# ioam3358 register map
Registers are 32-bit, access not given, no defined reset value unless marked. A register's access mark holds for its fields unless they carry their own. Addresses are absolute; registers are grouped by the start of their names; [hi:lo] are bit positions; {n}, {i} and the like mark numbered series; 'fields as' and 'values as' point back to an identical list.

## CPSW
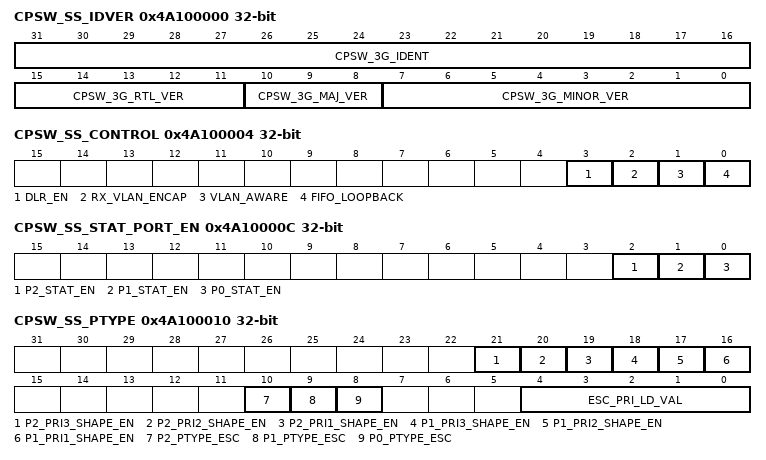
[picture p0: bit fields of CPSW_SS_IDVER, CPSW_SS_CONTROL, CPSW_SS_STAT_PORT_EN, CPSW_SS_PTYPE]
0x4A100000 CPSW_SS_IDVER
  [31:16] CPSW_3G_IDENT, [15:11] CPSW_3G_RTL_VER, [10:8] CPSW_3G_MAJ_VER, [7:0] CPSW_3G_MINOR_VER
0x4A100004 CPSW_SS_CONTROL
  [3] DLR_EN, [2] RX_VLAN_ENCAP, [1] VLAN_AWARE, [0] FIFO_LOOPBACK
0x4A100008 CPSW_SS_SOFT_RESET
  [0] SOFT_RESET
0x4A10000C CPSW_SS_STAT_PORT_EN
  [2] P2_STAT_EN, [1] P1_STAT_EN, [0] P0_STAT_EN
0x4A100010 CPSW_SS_PTYPE
  [21] P2_PRI3_SHAPE_EN, [20] P2_PRI2_SHAPE_EN, [19] P2_PRI1_SHAPE_EN, [18] P1_PRI3_SHAPE_EN, [17] P1_PRI2_SHAPE_EN, [16] P1_PRI1_SHAPE_EN, [10] P2_PTYPE_ESC, [9] P1_PTYPE_ESC, [8] P0_PTYPE_ESC, [4:0] ESC_PRI_LD_VAL
0x4A100014 CPSW_SS_SOFT_IDLE
  [0] SOFT_IDLE
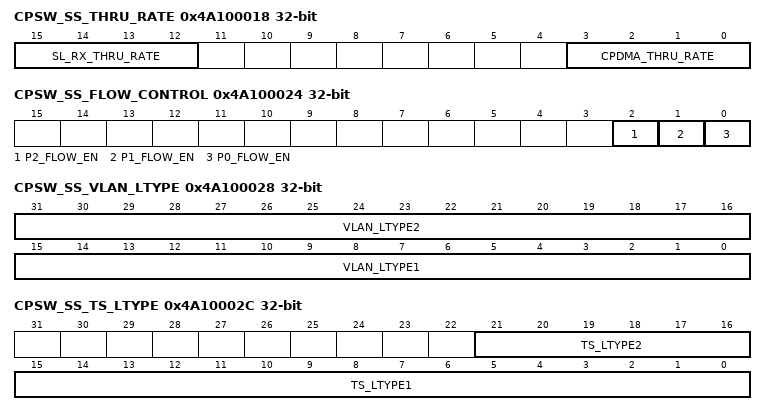
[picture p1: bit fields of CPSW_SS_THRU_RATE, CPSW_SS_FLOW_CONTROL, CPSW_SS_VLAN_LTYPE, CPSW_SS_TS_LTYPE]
0x4A100018 CPSW_SS_THRU_RATE
  [15:12] SL_RX_THRU_RATE, [3:0] CPDMA_THRU_RATE
0x4A10001C CPSW_SS_GAP_THRESH
  [4:0] GAP_THRESH
0x4A100020 CPSW_SS_TX_START_WDS
  [10:0] TX_START_WDS
0x4A100024 CPSW_SS_FLOW_CONTROL
  [2] P2_FLOW_EN, [1] P1_FLOW_EN, [0] P0_FLOW_EN
0x4A100028 CPSW_SS_VLAN_LTYPE
  [31:16] VLAN_LTYPE2, [15:0] VLAN_LTYPE1
0x4A10002C CPSW_SS_TS_LTYPE
  [21:16] TS_LTYPE2, [15:0] TS_LTYPE1
0x4A100030 CPSW_SS_DLR_LTYPE
  [15:0] DLR_LTYPE
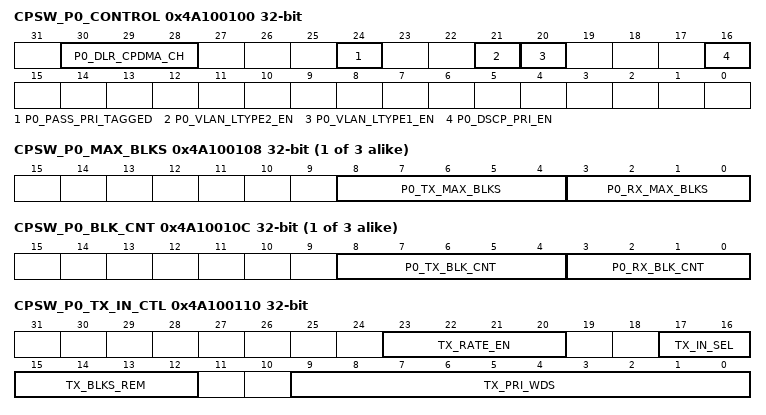
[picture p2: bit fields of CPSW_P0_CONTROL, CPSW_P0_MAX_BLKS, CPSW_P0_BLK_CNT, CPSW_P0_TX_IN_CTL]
0x4A100100 CPSW_P0_CONTROL
  [30:28] P0_DLR_CPDMA_CH, [24] P0_PASS_PRI_TAGGED, [21] P0_VLAN_LTYPE2_EN, [20] P0_VLAN_LTYPE1_EN, [16] P0_DSCP_PRI_EN
{0x4A100108+0x100*i} CPSW_P{i}_MAX_BLKS (i=0..2)
  [8:4] P{i}_TX_MAX_BLKS, [3:0] P{i}_RX_MAX_BLKS
{0x4A10010C+0x100*i} CPSW_P{i}_BLK_CNT (i=0..2)
  [8:4] P{i}_TX_BLK_CNT, [3:0] P{i}_RX_BLK_CNT
0x4A100110 CPSW_P0_TX_IN_CTL
  [23:20] TX_RATE_EN, [17:16] TX_IN_SEL, [15:12] TX_BLKS_REM, [9:0] TX_PRI_WDS
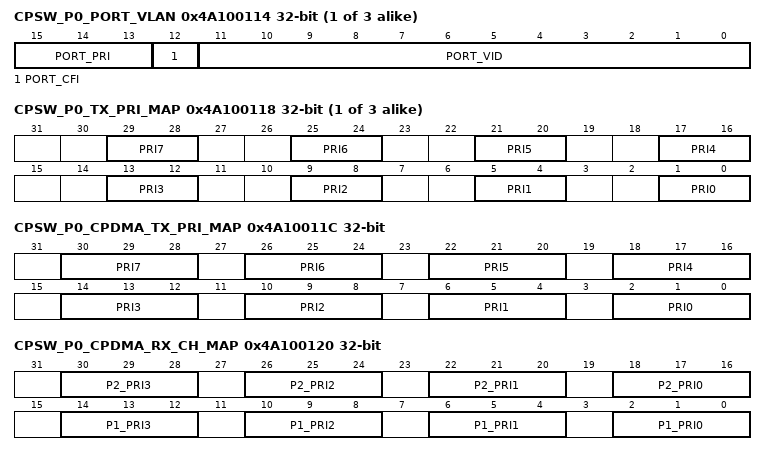
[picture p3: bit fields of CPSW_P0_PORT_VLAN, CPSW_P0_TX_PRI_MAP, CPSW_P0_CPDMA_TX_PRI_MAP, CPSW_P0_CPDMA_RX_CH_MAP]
{0x4A100114+0x100*i} CPSW_P{i}_PORT_VLAN (i=0..2)
  [15:13] PORT_PRI, [12] PORT_CFI, [11:0] PORT_VID
{0x4A100118+0x100*i} CPSW_P{i}_TX_PRI_MAP (i=0..2)
  [4n+1:4n] PRI{n} (n=0..7)
0x4A10011C CPSW_P0_CPDMA_TX_PRI_MAP
  [4n+2:4n] PRI{n} (n=0..7)
0x4A100120 CPSW_P0_CPDMA_RX_CH_MAP
  [4n+18:4n+16] P2_PRI{n} (n=0..3), [4n+2:4n] P1_PRI{n} (n=0..3)
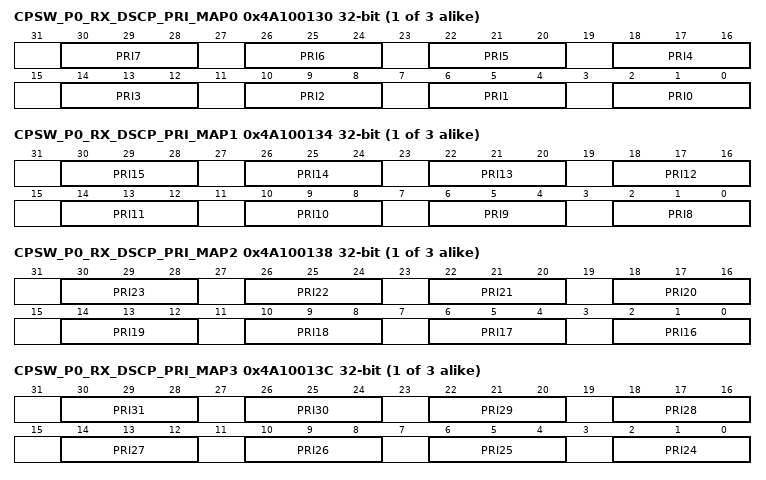
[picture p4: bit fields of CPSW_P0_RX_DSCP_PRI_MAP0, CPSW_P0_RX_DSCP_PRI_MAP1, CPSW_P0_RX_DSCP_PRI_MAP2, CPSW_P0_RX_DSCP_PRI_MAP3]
{0x4A100130+0x100*i} CPSW_P{i}_RX_DSCP_PRI_MAP0 (i=0..2)
  [4n+2:4n] PRI{n} (n=0..7)
{0x4A100134+0x100*i} CPSW_P{i}_RX_DSCP_PRI_MAP1 (i=0..2)
  [4n-30:4n-32] PRI{n} (n=8..15)
{0x4A100138+0x100*i} CPSW_P{i}_RX_DSCP_PRI_MAP2 (i=0..2)
  [4n-62:4n-64] PRI{n} (n=16..23)
{0x4A10013C+0x100*i} CPSW_P{i}_RX_DSCP_PRI_MAP3 (i=0..2)
  [4n-94:4n-96] PRI{n} (n=24..31)
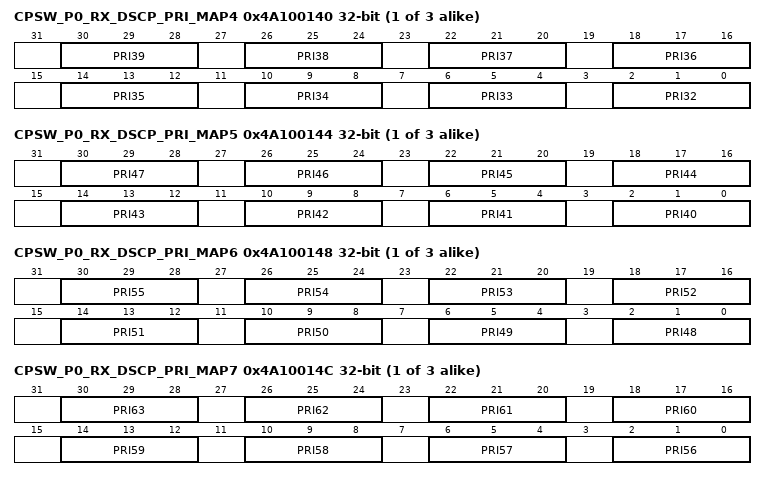
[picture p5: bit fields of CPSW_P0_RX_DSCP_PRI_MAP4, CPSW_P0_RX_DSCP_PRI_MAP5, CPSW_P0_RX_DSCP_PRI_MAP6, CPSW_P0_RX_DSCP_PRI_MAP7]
{0x4A100140+0x100*i} CPSW_P{i}_RX_DSCP_PRI_MAP4 (i=0..2)
  [4n-126:4n-128] PRI{n} (n=32..39)
{0x4A100144+0x100*i} CPSW_P{i}_RX_DSCP_PRI_MAP5 (i=0..2)
  [4n-158:4n-160] PRI{n} (n=40..47)
{0x4A100148+0x100*i} CPSW_P{i}_RX_DSCP_PRI_MAP6 (i=0..2)
  [4n-190:4n-192] PRI{n} (n=48..55)
{0x4A10014C+0x100*i} CPSW_P{i}_RX_DSCP_PRI_MAP7 (i=0..2)
  [4n-222:4n-224] PRI{n} (n=56..63)
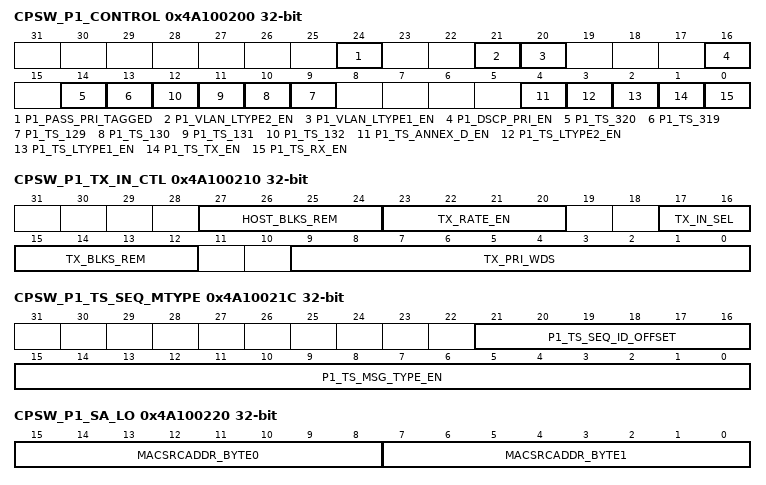
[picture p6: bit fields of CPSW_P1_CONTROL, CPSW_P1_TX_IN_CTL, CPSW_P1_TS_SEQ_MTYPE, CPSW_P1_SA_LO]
0x4A100200 CPSW_P1_CONTROL
  [24] P1_PASS_PRI_TAGGED, [21] P1_VLAN_LTYPE2_EN, [20] P1_VLAN_LTYPE1_EN, [16] P1_DSCP_PRI_EN, [14] P1_TS_320, [13] P1_TS_319, [n-120] P1_TS_{n} (n=129..132), [4] P1_TS_ANNEX_D_EN, [3] P1_TS_LTYPE2_EN, [2] P1_TS_LTYPE1_EN, [1] P1_TS_TX_EN, [0] P1_TS_RX_EN
0x4A100210 CPSW_P1_TX_IN_CTL
  [27:24] HOST_BLKS_REM, [23:20] TX_RATE_EN, [17:16] TX_IN_SEL, [15:12] TX_BLKS_REM, [9:0] TX_PRI_WDS
0x4A10021C CPSW_P1_TS_SEQ_MTYPE
  [21:16] P1_TS_SEQ_ID_OFFSET, [15:0] P1_TS_MSG_TYPE_EN
0x4A100220 CPSW_P1_SA_LO
  [15:8] MACSRCADDR_BYTE0, [7:0] MACSRCADDR_BYTE1
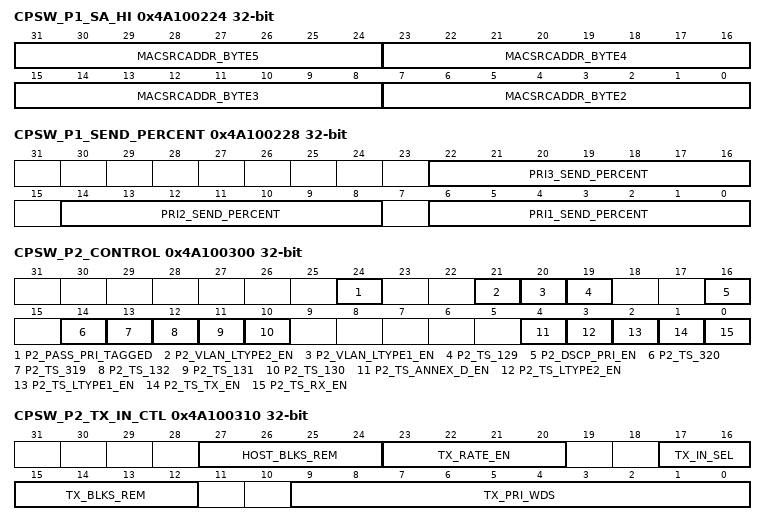
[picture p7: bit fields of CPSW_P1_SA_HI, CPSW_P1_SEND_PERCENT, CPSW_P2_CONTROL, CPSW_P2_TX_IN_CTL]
0x4A100224 CPSW_P1_SA_HI
  [8n-9:8n-16] MACSRCADDR_BYTE{n} (n=2..5)
0x4A100228 CPSW_P1_SEND_PERCENT
  [22:16] PRI3_SEND_PERCENT, [14:8] PRI2_SEND_PERCENT, [6:0] PRI1_SEND_PERCENT
0x4A100300 CPSW_P2_CONTROL
  [24] P2_PASS_PRI_TAGGED, [21] P2_VLAN_LTYPE2_EN, [20] P2_VLAN_LTYPE1_EN, [19] P2_TS_129, [16] P2_DSCP_PRI_EN, [14] P2_TS_320, [13] P2_TS_319, [12] P2_TS_132, [11] P2_TS_131, [10] P2_TS_130, [4] P2_TS_ANNEX_D_EN, [3] P2_TS_LTYPE2_EN, [2] P2_TS_LTYPE1_EN, [1] P2_TS_TX_EN, [0] P2_TS_RX_EN
0x4A100310 CPSW_P2_TX_IN_CTL
  fields as CPSW_P1_TX_IN_CTL
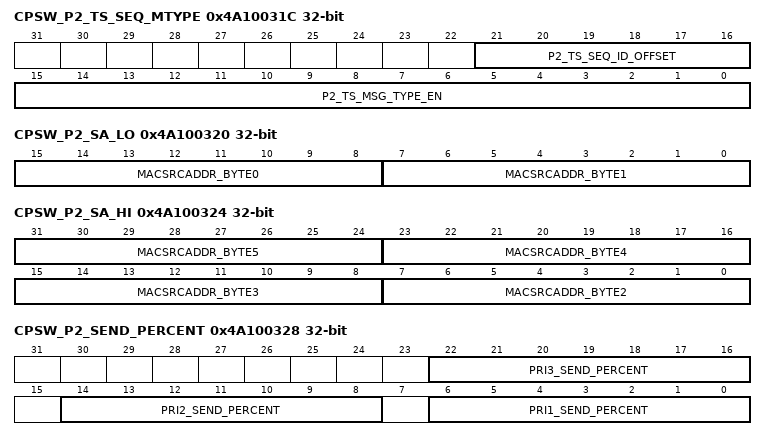
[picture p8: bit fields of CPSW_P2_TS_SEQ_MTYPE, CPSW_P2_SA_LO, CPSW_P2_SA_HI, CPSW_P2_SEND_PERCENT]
0x4A10031C CPSW_P2_TS_SEQ_MTYPE
  [21:16] P2_TS_SEQ_ID_OFFSET, [15:0] P2_TS_MSG_TYPE_EN
0x4A100320 CPSW_P2_SA_LO
  [15:8] MACSRCADDR_BYTE0, [7:0] MACSRCADDR_BYTE1
0x4A100324 CPSW_P2_SA_HI
  [8n-9:8n-16] MACSRCADDR_BYTE{n} (n=2..5)
0x4A100328 CPSW_P2_SEND_PERCENT
  fields as CPSW_P1_SEND_PERCENT
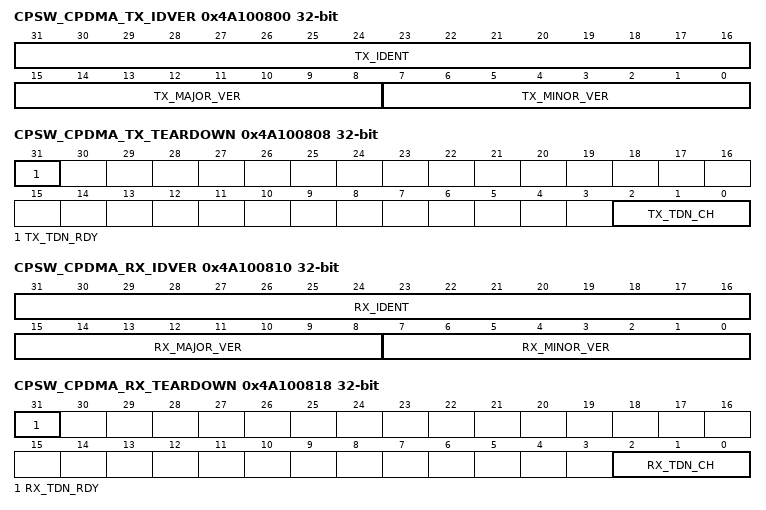
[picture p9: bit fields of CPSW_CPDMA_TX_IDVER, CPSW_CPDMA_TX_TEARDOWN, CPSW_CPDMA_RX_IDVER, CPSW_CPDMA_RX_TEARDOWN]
0x4A100800 CPSW_CPDMA_TX_IDVER
  [31:16] TX_IDENT, [15:8] TX_MAJOR_VER, [7:0] TX_MINOR_VER
0x4A100804 CPSW_CPDMA_TX_CONTROL
  [0] TX_EN
0x4A100808 CPSW_CPDMA_TX_TEARDOWN
  [31] TX_TDN_RDY, [2:0] TX_TDN_CH
0x4A100810 CPSW_CPDMA_RX_IDVER
  [31:16] RX_IDENT, [15:8] RX_MAJOR_VER, [7:0] RX_MINOR_VER
0x4A100814 CPSW_CPDMA_RX_CONTROL
  [0] RX_EN
0x4A100818 CPSW_CPDMA_RX_TEARDOWN
  [31] RX_TDN_RDY, [2:0] RX_TDN_CH
0x4A10081C CPSW_CPDMA_CPDMA_SOFT_RESET
  [0] SOFT_RESET
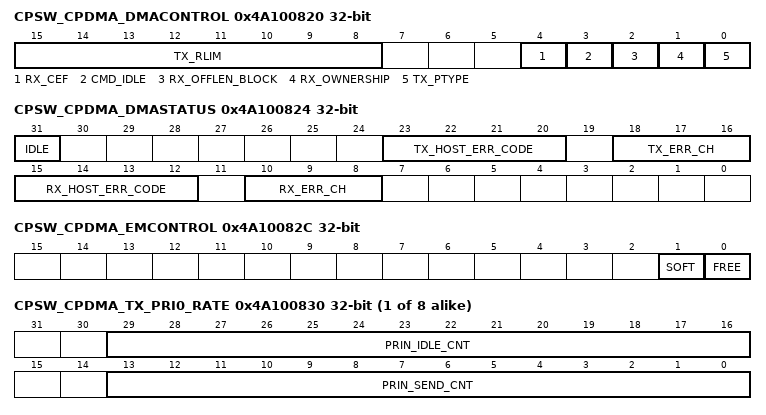
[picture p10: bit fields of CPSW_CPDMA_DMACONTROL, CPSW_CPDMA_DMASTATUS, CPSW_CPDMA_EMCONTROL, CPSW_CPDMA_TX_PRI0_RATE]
0x4A100820 CPSW_CPDMA_DMACONTROL
  [15:8] TX_RLIM, [4] RX_CEF, [3] CMD_IDLE, [2] RX_OFFLEN_BLOCK, [1] RX_OWNERSHIP, [0] TX_PTYPE
0x4A100824 CPSW_CPDMA_DMASTATUS
  [31] IDLE, [23:20] TX_HOST_ERR_CODE, [18:16] TX_ERR_CH, [15:12] RX_HOST_ERR_CODE, [10:8] RX_ERR_CH
0x4A100828 CPSW_CPDMA_RX_BUFFER_OFFSET
  [15:0] RX_BUFFER_OFFSET
0x4A10082C CPSW_CPDMA_EMCONTROL
  [1] SOFT, [0] FREE
{0x4A100830+4i} CPSW_CPDMA_TX_PRI{i}_RATE (i=0..7)
  [29:16] PRIN_IDLE_CNT, [13:0] PRIN_SEND_CNT
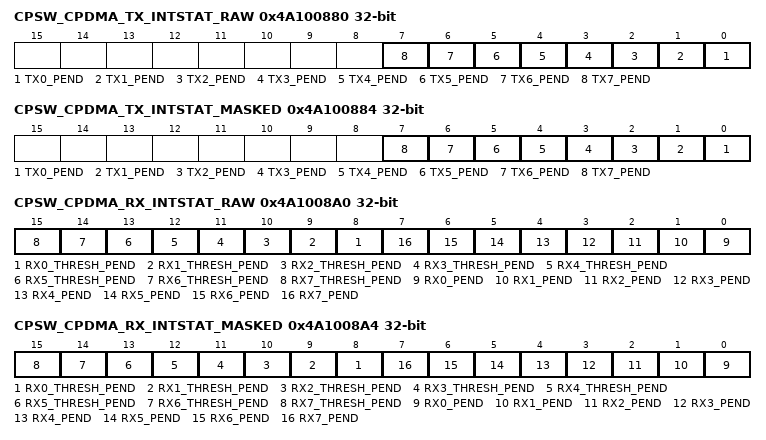
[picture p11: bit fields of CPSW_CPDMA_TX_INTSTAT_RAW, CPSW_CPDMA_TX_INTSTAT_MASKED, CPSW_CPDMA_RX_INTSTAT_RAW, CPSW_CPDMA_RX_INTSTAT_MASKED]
0x4A100880 CPSW_CPDMA_TX_INTSTAT_RAW
  [n] TX{n}_PEND (n=0..7)
0x4A100884 CPSW_CPDMA_TX_INTSTAT_MASKED
  [n] TX{n}_PEND (n=0..7)
0x4A100888 CPSW_CPDMA_TX_INTMASK_SET
0x4A10088C CPSW_CPDMA_TX_INTMASK_CLEAR
0x4A100890 CPSW_CPDMA_IN_VECTOR
0x4A100894 CPSW_CPDMA_EOI_VECTOR
  [4:0] DMA_EOI_VECTOR
0x4A1008A0 CPSW_CPDMA_RX_INTSTAT_RAW
  [n+8] RX{n}_THRESH_PEND (n=0..7), [n] RX{n}_PEND (n=0..7)
0x4A1008A4 CPSW_CPDMA_RX_INTSTAT_MASKED
  [n+8] RX{n}_THRESH_PEND (n=0..7), [n] RX{n}_PEND (n=0..7)
0x4A1008A8 CPSW_CPDMA_RX_INTMASK_SET
0x4A1008AC CPSW_CPDMA_RX_INTMASK_CLEAR
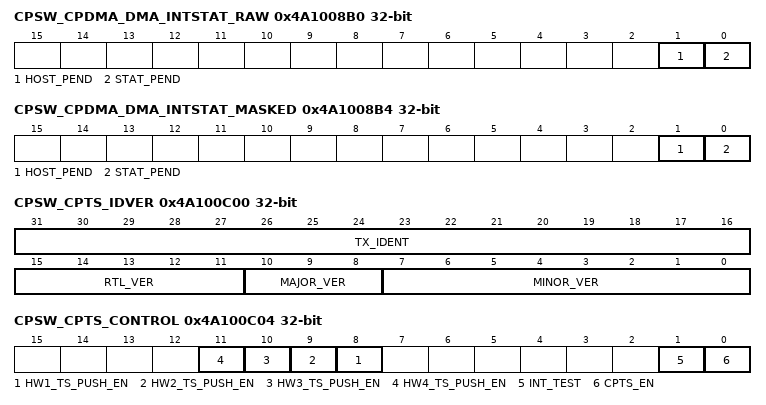
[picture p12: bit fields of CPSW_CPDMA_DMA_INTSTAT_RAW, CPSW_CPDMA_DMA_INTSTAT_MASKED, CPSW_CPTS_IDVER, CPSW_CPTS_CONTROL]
0x4A1008B0 CPSW_CPDMA_DMA_INTSTAT_RAW
  [1] HOST_PEND, [0] STAT_PEND
0x4A1008B4 CPSW_CPDMA_DMA_INTSTAT_MASKED
  [1] HOST_PEND, [0] STAT_PEND
0x4A1008B8 CPSW_CPDMA_DMA_INTMASK_SET
0x4A1008BC CPSW_CPDMA_DMA_INTMASK_CLEAR
{0x4A1008C0+4i} CPSW_CPDMA_RX{i}_PENDTHRESH (i=0..7)
  [7:0] RX_PENDTHRESH
{0x4A1008E0+4i} CPSW_CPDMA_RX{i}_FREEBUFFER (i=0..7)
  [15:0] RX_FREEBUFFER
{0x4A100A00+4i} CPSW_CPDMA_TX{i}_HDP (i=0..7)
{0x4A100A20+4i} CPSW_CPDMA_RX{i}_HDP (i=0..7)
{0x4A100A40+4i} CPSW_CPDMA_TX{i}_CP (i=0..7)
{0x4A100A60+4i} CPSW_CPDMA_RX{i}_CP (i=0..7)
0x4A100C00 CPSW_CPTS_IDVER
  [31:16] TX_IDENT, [15:11] RTL_VER, [10:8] MAJOR_VER, [7:0] MINOR_VER
0x4A100C04 CPSW_CPTS_CONTROL
  [n+7] HW{n}_TS_PUSH_EN (n=1..4), [1] INT_TEST, [0] CPTS_EN
0x4A100C0C CPSW_CPTS_TS_PUSH
0x4A100C10 CPSW_CPTS_TS_LOAD_VAL
0x4A100C14 CPSW_CPTS_TS_LOAD_EN
0x4A100C20 CPSW_CPTS_INTSTAT_RAW
  [0] TS_PEND_RAW
0x4A100C24 CPSW_CPTS_INTSTAT_MASKED
  [0] TS_PEND
0x4A100C28 CPSW_CPTS_INT_ENABLE
  [0] TS_PEND_EN
0x4A100C30 CPSW_CPTS_EVENT_POP
0x4A100C34 CPSW_CPTS_EVENT_LOW
  [31:0] TIME_STAMP
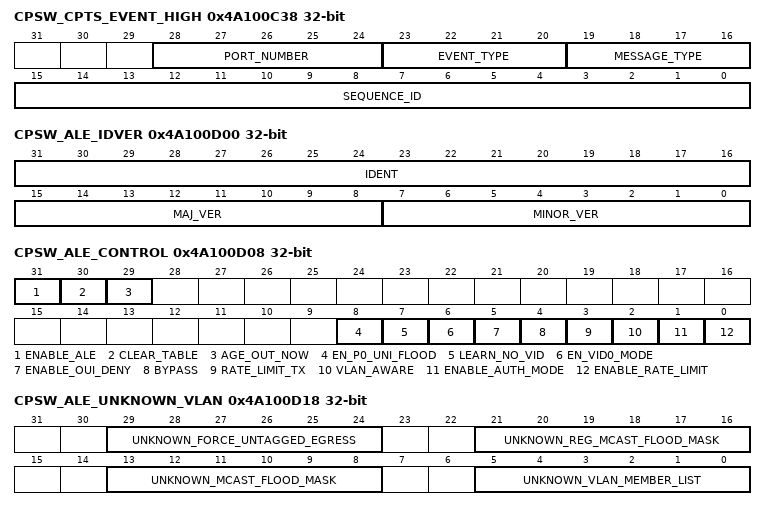
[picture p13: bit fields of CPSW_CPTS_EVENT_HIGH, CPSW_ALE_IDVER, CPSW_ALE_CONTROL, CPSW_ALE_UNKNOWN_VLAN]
0x4A100C38 CPSW_CPTS_EVENT_HIGH
  [28:24] PORT_NUMBER, [23:20] EVENT_TYPE, [19:16] MESSAGE_TYPE, [15:0] SEQUENCE_ID
0x4A100D00 CPSW_ALE_IDVER
  [31:16] IDENT, [15:8] MAJ_VER, [7:0] MINOR_VER
0x4A100D08 CPSW_ALE_CONTROL
  [31] ENABLE_ALE, [30] CLEAR_TABLE, [29] AGE_OUT_NOW, [8] EN_P0_UNI_FLOOD, [7] LEARN_NO_VID, [6] EN_VID0_MODE, [5] ENABLE_OUI_DENY, [4] BYPASS, [3] RATE_LIMIT_TX, [2] VLAN_AWARE, [1] ENABLE_AUTH_MODE, [0] ENABLE_RATE_LIMIT
0x4A100D10 CPSW_ALE_PRESCALE
  [19:0] PRESCALE
0x4A100D18 CPSW_ALE_UNKNOWN_VLAN
  [29:24] UNKNOWN_FORCE_UNTAGGED_EGRESS, [21:16] UNKNOWN_REG_MCAST_FLOOD_MASK, [13:8] UNKNOWN_MCAST_FLOOD_MASK, [5:0] UNKNOWN_VLAN_MEMBER_LIST
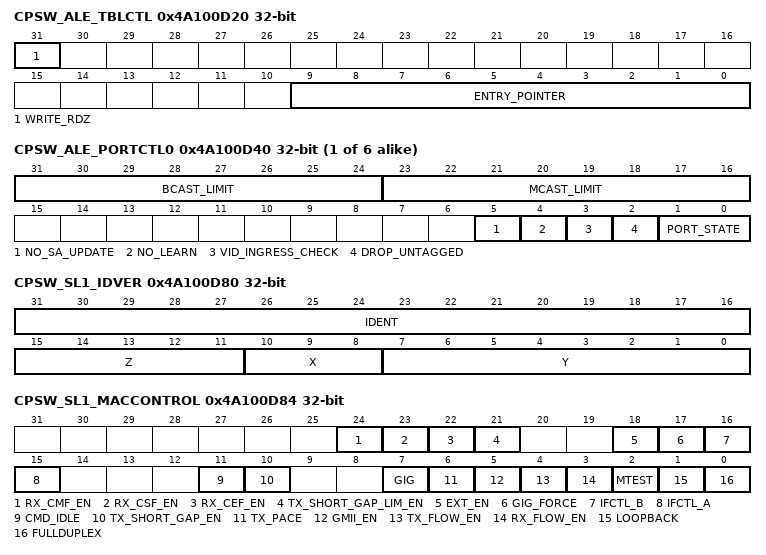
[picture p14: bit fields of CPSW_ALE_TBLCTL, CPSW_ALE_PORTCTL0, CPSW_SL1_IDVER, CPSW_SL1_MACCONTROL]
0x4A100D20 CPSW_ALE_TBLCTL
  [31] WRITE_RDZ, [9:0] ENTRY_POINTER
0x4A100D34 CPSW_ALE_TBLW2
0x4A100D38 CPSW_ALE_TBLW1
0x4A100D3C CPSW_ALE_TBLW0
{0x4A100D40+4i} CPSW_ALE_PORTCTL{i} (i=0..5)
  [31:24] BCAST_LIMIT, [23:16] MCAST_LIMIT, [5] NO_SA_UPDATE, [4] NO_LEARN, [3] VID_INGRESS_CHECK, [2] DROP_UNTAGGED, [1:0] PORT_STATE
0x4A100D80 CPSW_SL1_IDVER
  [31:16] IDENT, [15:11] Z, [10:8] X, [7:0] Y
0x4A100D84 CPSW_SL1_MACCONTROL
  [24] RX_CMF_EN, [23] RX_CSF_EN, [22] RX_CEF_EN, [21] TX_SHORT_GAP_LIM_EN, [18] EXT_EN, [17] GIG_FORCE, [16] IFCTL_B, [15] IFCTL_A, [11] CMD_IDLE, [10] TX_SHORT_GAP_EN, [7] GIG, [6] TX_PACE, [5] GMII_EN, [4] TX_FLOW_EN, [3] RX_FLOW_EN, [2] MTEST, [1] LOOPBACK, [0] FULLDUPLEX
0x4A100D88 CPSW_SL1_MACSTATUS
  [31] IDLE, [4] EXT_GIG, [3] EXT_FULLDUPLEX, [1] RX_FLOW_ACT, [0] TX_FLOW_ACT
0x4A100D8C CPSW_SL1_SOFT_RESET
  [0] SOFT_RESET
0x4A100D90 CPSW_SL1_RX_MAXLEN
  [13:0] RX_MAXLEN
0x4A100D94 CPSW_SL1_BOFFTEST
  [30:26] PACEVAL, [25:16] RNDNUM, [15:12] COLL_COUNT, [9:0] TX_BACKOFF
0x4A100D98 CPSW_SL1_RX_PAUSE
  [31:16] RX_PAUSETIMER
0x4A100D9C CPSW_SL1_TX_PAUSE
  [31:16] TX_PAUSETIMER
0x4A100DA0 CPSW_SL1_EMCONTROL
  [1] SOF, [0] FREE
0x4A100DA4 CPSW_SL1_RX_PRI_MAP
  [4n+2:4n] PRI{n} (n=0..7)
0x4A100DA8 CPSW_SL1_TX_GAP
  [8:0] TX_GAP
0x4A100DC0 CPSW_SL2_IDVER
  [31:16] IDENT, [15:11] Z, [10:8] X, [7:0] Y
0x4A100DC4 CPSW_SL2_MACCONTROL
  fields as CPSW_SL1_MACCONTROL
0x4A100DC8 CPSW_SL2_MACSTATUS
  fields as CPSW_SL1_MACSTATUS
0x4A100DCC CPSW_SL2_SOFT_RESET
  [0] SOFT_RESET
0x4A100DD0 CPSW_SL2_RX_MAXLEN
  [13:0] RX_MAXLEN
0x4A100DD4 CPSW_SL2_BOFFTEST
  fields as CPSW_SL1_BOFFTEST
0x4A100DD8 CPSW_SL2_RX_PAUSE
  [31:16] RX_PAUSETIMER
0x4A100DDC CPSW_SL2_TX_PAUSE
  [31:16] TX_PAUSETIMER
0x4A100DE0 CPSW_SL2_EMCONTROL
  [1] SOF, [0] FREE
0x4A100DE4 CPSW_SL2_RX_PRI_MAP
  [4n+2:4n] PRI{n} (n=0..7)
0x4A100DE8 CPSW_SL2_TX_GAP
  [8:0] TX_GAP
0x4A101200 CPSW_WR_IDVER
  [31:30] SCHEME, [27:16] FUNCTION, [15:11] RTL, [10:8] MAJOR, [7:6] CUSTOM, [5:0] MINOR
0x4A101204 CPSW_WR_SOFT_RESET
  [0] SOFT_RESET
0x4A101208 CPSW_WR_CONTROL
  [3:2] MMR_STDBYMODE, [1:0] MMR_IDLEMODE
0x4A10120C CPSW_WR_INT_CONTROL
  [31] INT_TEST, [n+16] INT_PACE_EN{n} (n=0..5), [11:0] INT_PRESCALE
{0x4A101210+0x10*i} CPSW_WR_C{i}_RX_THRESH_EN (i=0..2)
  [n] C{i}_RX_THRESH_EN{n} (n=0..7)
{0x4A101214+0x10*i} CPSW_WR_C{i}_RX_EN (i=0..2)
  [n] C{i}_RX_EN{n} (n=0..7)
{0x4A101218+0x10*i} CPSW_WR_C{i}_TX_EN (i=0..2)
  [n] C{i}_TX_EN{n} (n=0..7)
{0x4A10121C+0x10*i} CPSW_WR_C{i}_MISC_EN (i=0..2)
  [n] C{i}_MISC_EN{n} (n=0..4)
{0x4A101240+0x10*i} CPSW_WR_C{i}_RX_THRESH_STAT (i=0..2)
  [n] C{i}_RX_THRESH_STAT{n} (n=0..7)
{0x4A101244+0x10*i} CPSW_WR_C{i}_RX_STAT (i=0..2)
  [n] C{i}_RX_STAT{n} (n=0..7)
{0x4A101248+0x10*i} CPSW_WR_C{i}_TX_STAT (i=0..2)
  [n] C{i}_TX_STAT{n} (n=0..7)
{0x4A10124C+0x10*i} CPSW_WR_C{i}_MISC_STAT (i=0..2)
  [n] C{i}_MISC_STAT{n} (n=0..4)
{0x4A101270+8i} CPSW_WR_C{i}_RX_IMAX (i=0..2)
  [5:0] C{i}_RX_IMAX
{0x4A101274+8i} CPSW_WR_C{i}_TX_IMAX (i=0..2)
  [5:0] C{i}_TX_IMAX
0x4A101288 CPSW_WR_RGMII_CTL
  [7] RGMII2_FULLDUPLEX, [6:5] RGMII2_SPEED, [4] RGMII2_LINK, [3] RGMII1_FULLDUPLEX, [2:1] RGMII1_SPEED, [0] RGMII1_LINK
